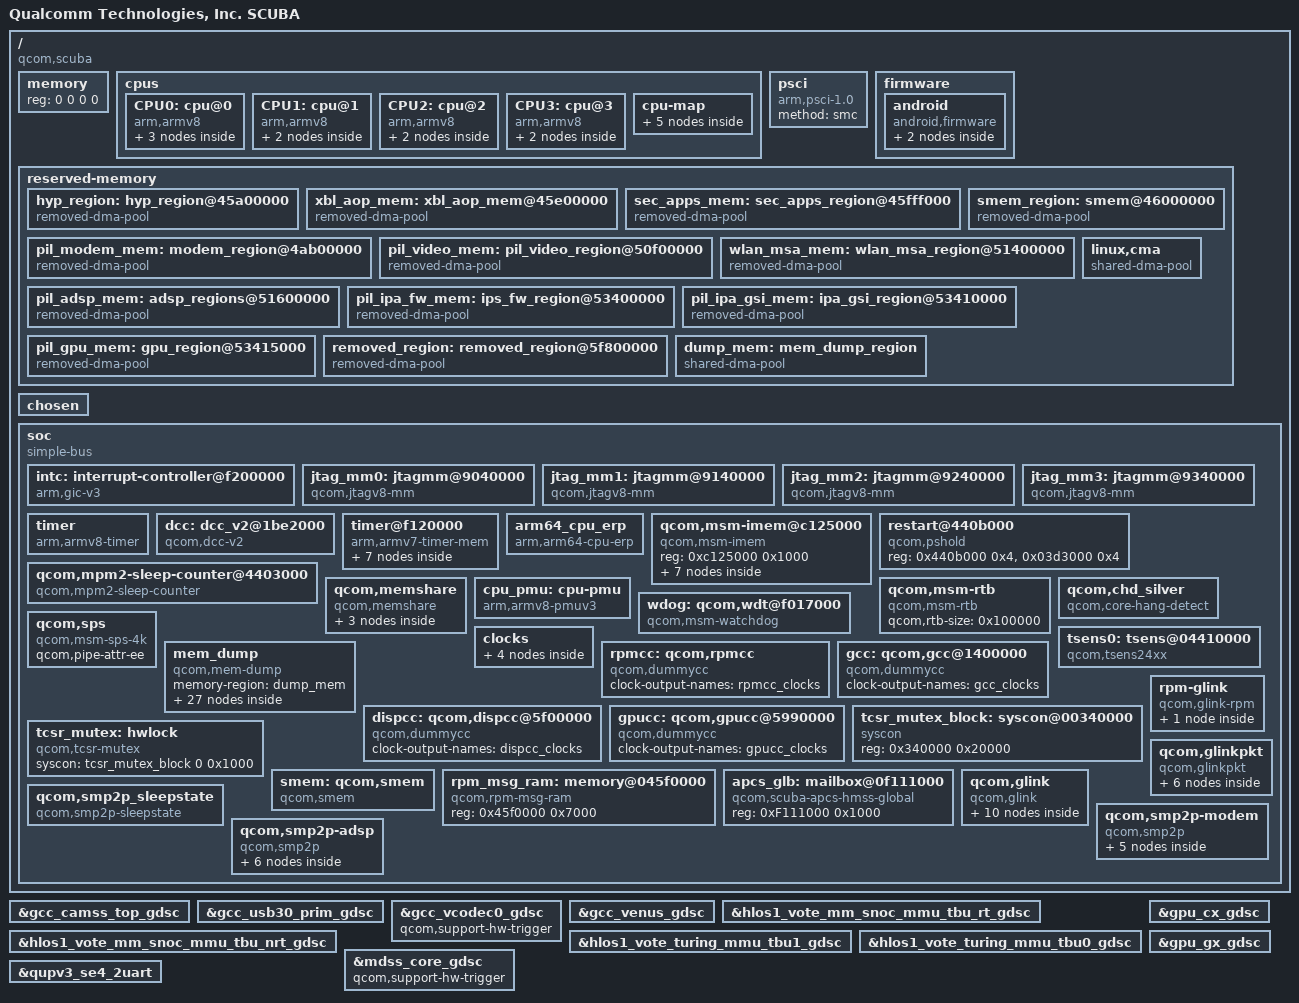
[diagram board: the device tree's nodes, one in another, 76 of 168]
#include <dt-bindings/interrupt-controller/arm-gic.h>
#include <dt-bindings/clock/qcom,dispcc-scuba.h>
#include <dt-bindings/clock/qcom,gcc-scuba.h>
#include <dt-bindings/clock/qcom,gpucc-scuba.h>
#include <dt-bindings/clock/qcom,rpmcc.h>

/ {
	model = "Qualcomm Technologies, Inc. SCUBA";
	compatible = "qcom,scuba";
	qcom,msm-id = <441 0x10000>;
	interrupt-parent = <&intc>;

	#address-cells = <2>;
	#size-cells = <2>;
	memory { device_type = "memory"; reg = <0 0 0 0>; };

	cpus {
		#address-cells = <2>;
		#size-cells = <0>;

		CPU0: cpu@0 {
			device_type = "cpu";
			compatible = "arm,armv8";
			reg = <0x0 0x0>;
			enable-method = "psci";
			capacity-dmips-mhz = <1024>;
			dynamic-power-coefficient = <100>;
			d-cache-size = <0x8000>;
			i-cache-size = <0x8000>;
			next-level-cache = <&L2_0>;
			L2_0: l2-cache {
				compatible = "arm,arch-cache";
				cache-level = <2>;
			};

			L1_I_0: l1-icache {
				compatible = "arm,arch-cache";
			};

			L1_D_0: l1-dcache {
				compatible = "arm,arch-cache";
			};
		};

		CPU1: cpu@1 {
			device_type = "cpu";
			compatible = "arm,armv8";
			reg = <0x0 0x1>;
			enable-method = "psci";
			capacity-dmips-mhz = <1024>;
			dynamic-power-coefficient = <100>;
			d-cache-size = <0x8000>;
			i-cache-size = <0x8000>;
			next-level-cache = <&L2_0>;

			L1_I_1: l1-icache {
				compatible = "arm,arch-cache";
			};

			L1_D_1: l1-dcache {
				compatible = "arm,arch-cache";
			};
		};

		CPU2: cpu@2 {
			device_type = "cpu";
			compatible = "arm,armv8";
			reg = <0x0 0x2>;
			enable-method = "psci";
			capacity-dmips-mhz = <1024>;
			dynamic-power-coefficient = <100>;
			d-cache-size = <0x8000>;
			i-cache-size = <0x8000>;
			next-level-cache = <&L2_0>;

			L1_I_2: l1-icache {
				compatible = "arm,arch-cache";
			};

			L1_D_2: l1-dcache {
				compatible = "arm,arch-cache";
			};
		};

		CPU3: cpu@3 {
			device_type = "cpu";
			compatible = "arm,armv8";
			reg = <0x0 0x3>;
			enable-method = "psci";
			capacity-dmips-mhz = <1024>;
			dynamic-power-coefficient = <100>;
			d-cache-size = <0x8000>;
			i-cache-size = <0x8000>;
			next-level-cache = <&L2_0>;

			L1_I_3: l1-icache {
				compatible = "arm,arch-cache";
			};

			L1_D_3: l1-dcache {
				compatible = "arm,arch-cache";
			};
		};

		cpu-map {
			cluster0 {
				core0 {
					cpu = <&CPU0>;
				};

				core1 {
					cpu = <&CPU1>;
				};

				core2 {
					cpu = <&CPU2>;
				};

				core3 {
					cpu = <&CPU3>;
				};
			};
		};
	};

	psci {
		compatible = "arm,psci-1.0";
		method = "smc";
	};

	firmware: firmware {
		android {
			compatible = "android,firmware";
			fstab {
				compatible = "android,fstab";
				vendor {
					compatible = "android,vendor";
					dev = "/dev/block/platform/soc/4744000.sdhci/by-name/vendor";
					type = "ext4";
					mnt_flags = "ro,barrier=1,discard";
					fsmgr_flags = "wait,slotselect";
					status = "ok";
				};
			};
		};
	};

	reserved-memory {
		#address-cells = <2>;
		#size-cells = <2>;
		ranges;

		hyp_region: hyp_region@45a00000 {
			compatible = "removed-dma-pool";
			no-map;
			reg = <0x0 0x45a00000 0x0 0x300000>;
		};

		xbl_aop_mem: xbl_aop_mem@45e00000 {
			compatible = "removed-dma-pool";
			no-map;
			reg = <0x0 0x45e00000 0x0 0x100000>;
		};

		sec_apps_mem: sec_apps_region@45fff000 {
			compatible = "removed-dma-pool";
			no-map;
			reg = <0x0 0x45fff000 0x0 0x1000>;
		};

		smem_region: smem@46000000 {
			compatible = "removed-dma-pool";
			no-map;
			reg = <0x0 0x46000000 0x0 0x200000>;
		};

		pil_modem_mem: modem_region@4ab00000 {
			compatible = "removed-dma-pool";
			no-map;
			reg = <0x0 0x4ab00000 0x0 0x6400000>;
		};

		pil_video_mem: pil_video_region@50f00000 {
			compatible = "removed-dma-pool";
			no-map;
			reg = <0x0 0x50f00000 0x0 0x500000>;
		};

		wlan_msa_mem: wlan_msa_region@51400000 {
			compatible = "removed-dma-pool";
			no-map;
			reg = <0x0 0x51400000 0x0 0x200000>;
		};

		pil_adsp_mem: adsp_regions@51600000 {
			compatible = "removed-dma-pool";
			no-map;
			reg = <0x0 0x51600000 0x0 0x1e00000>;
		};

		pil_ipa_fw_mem: ips_fw_region@53400000 {
			compatible = "removed-dma-pool";
			no-map;
			reg = <0x0 0x53400000 0x0 0x10000>;
		};

		pil_ipa_gsi_mem: ipa_gsi_region@53410000 {
			compatible = "removed-dma-pool";
			no-map;
			reg = <0x0 0x53410000 0x0 0x5000>;
		};

		pil_gpu_mem: gpu_region@53415000 {
			compatible = "removed-dma-pool";
			no-map;
			reg = <0x0 0x53415000 0x0 0x2000>;
		};

		removed_region: removed_region@5f800000 {
			compatible = "removed-dma-pool";
			no-map;
			reg = <0x0 0x5f800000 0x0 0x4100000>;
		};

		dump_mem: mem_dump_region {
			compatible = "shared-dma-pool";
			reusable;
			size = <0 0x800000>;
		};

		/* global autoconfigured region for contiguous allocations */
		linux,cma {
			compatible = "shared-dma-pool";
			alloc-ranges = <0x0 0x00000000 0x0 0xffffffff>;
			reusable;
			alignment = <0x0 0x400000>;
			size = <0x0 0x2000000>;
			linux,cma-default;
		};
	};

	chosen {
		bootargs = "rcupdate.rcu_expedited=1 rcu_nocbs=0-7";
	};

	soc: soc { };
};

&soc {
	#address-cells = <1>;
	#size-cells = <1>;
	ranges = <0 0 0 0xffffffff>;
	compatible = "simple-bus";

	intc: interrupt-controller@f200000 {
		compatible = "arm,gic-v3";
		#interrupt-cells = <3>;
		interrupt-controller;
		#redistributor-regions = <1>;
		redistributor-stride = <0x0 0x20000>;
		reg = <0xf200000 0x10000>,     /* GICD */
		      <0xf300000 0x100000>;    /* GICR * 8 */
		interrupts = <1 9 4>;
	};

	jtag_mm0: jtagmm@9040000 {
		compatible = "qcom,jtagv8-mm";
		reg = <0x9040000 0x1000>;
		reg-names = "etm-base";

		clocks = <&rpmcc RPM_SMD_QDSS_CLK>;
		clock-names = "core_clk";

		qcom,coresight-jtagmm-cpu = <&CPU0>;
	};

	jtag_mm1: jtagmm@9140000 {
		compatible = "qcom,jtagv8-mm";
		reg = <0x9140000 0x1000>;
		reg-names = "etm-base";

		clocks = <&rpmcc RPM_SMD_QDSS_CLK>;
		clock-names = "core_clk";

		qcom,coresight-jtagmm-cpu = <&CPU1>;
	};

	jtag_mm2: jtagmm@9240000 {
		compatible = "qcom,jtagv8-mm";
		reg = <0x9240000 0x1000>;
		reg-names = "etm-base";

		clocks = <&rpmcc RPM_SMD_QDSS_CLK>;
		clock-names = "core_clk";

		qcom,coresight-jtagmm-cpu = <&CPU2>;
	};

	jtag_mm3: jtagmm@9340000 {
		compatible = "qcom,jtagv8-mm";
		reg = <0x9340000 0x1000>;
		reg-names = "etm-base";

		clocks = <&rpmcc RPM_SMD_QDSS_CLK>;
		clock-names = "core_clk";

		qcom,coresight-jtagmm-cpu = <&CPU3>;
	};

	timer {
		compatible = "arm,armv8-timer";
		interrupts = <1 1 0xf08>,
			     <1 2 0xf08>,
			     <1 3 0xf08>,
			     <1 0 0xf08>;
		clock-frequency = <19200000>;
	};

	dcc: dcc_v2@1be2000 {
		compatible = "qcom,dcc-v2";
		reg = <0x1be2000 0x1000>,
			<0x1bee000 0x2000>;
		reg-names = "dcc-base", "dcc-ram-base";
		dcc-ram-offset = <0x2000>;
	};

	timer@f120000 {
		#address-cells = <1>;
		#size-cells = <1>;
		ranges;
		compatible = "arm,armv7-timer-mem";
		reg = <0xf120000 0x1000>;
		clock-frequency = <19200000>;

		frame@f121000 {
			frame-number = <0>;
			interrupts = <0 8 0x4>,
				     <0 7 0x4>;
			reg = <0xf121000 0x1000>,
			      <0xf122000 0x1000>;
		};

		frame@f123000 {
			frame-number = <1>;
			interrupts = <0 9 0x4>;
			reg = <0xf123000 0x1000>;
			status = "disabled";
		};

		frame@f124000 {
			frame-number = <2>;
			interrupts = <0 10 0x4>;
			reg = <0xf124000 0x1000>;
			status = "disabled";
		};

		frame@f125000 {
			frame-number = <3>;
			interrupts = <0 11 0x4>;
			reg = <0xf125000 0x1000>;
			status = "disabled";
		};

		frame@f126000 {
			frame-number = <4>;
			interrupts = <0 12 0x4>;
			reg = <0xf126000 0x1000>;
			status = "disabled";
		};

		frame@f127000 {
			frame-number = <5>;
			interrupts = <0 13 0x4>;
			reg = <0xf127000 0x1000>;
			status = "disabled";
		};

		frame@f128000 {
			frame-number = <6>;
			interrupts = <0 14 0x4>;
			reg = <0xf128000 0x1000>;
			status = "disabled";
		};
	};

	arm64_cpu_erp {
		compatible = "arm,arm64-cpu-erp";
		interrupt-names = "pri-dbe-irq",
				  "pri-ext-irq";
		interrupts = <0 43 4>,
			     <0 41 4>;
		poll-delay-ms = <5000>;
	};

	qcom,msm-imem@c125000 {
		compatible = "qcom,msm-imem";
		reg = <0xc125000 0x1000>;
		ranges = <0x0 0xc125000 0x1000>;
		#address-cells = <1>;
		#size-cells = <1>;

		mem_dump_table@10 {
			compatible = "qcom,msm-imem-mem_dump_table";
			reg = <0x10 0x8>;
		};

		restart_reason@65c {
			compatible = "qcom,msm-imem-restart_reason";
			reg = <0x65c 0x4>;
		};

		dload_type@1c {
			compatible = "qcom,msm-imem-dload-type";
			reg = <0x1c 0x4>;
		};

		boot_stats@6b0 {
			compatible = "qcom,msm-imem-boot_stats";
			reg = <0x6b0 0x20>;
		};

		kaslr_offset@6d0 {
			compatible = "qcom,msm-imem-kaslr_offset";
			reg = <0x6d0 0xc>;
		};

		pil@94c {
			compatible = "qcom,msm-imem-pil";
			reg = <0x94c 0xc8>;
		};

		diag_dload@c8 {
			compatible = "qcom,msm-imem-diag-dload";
			reg = <0xc8 0xc8>;
		};
	};

	restart@440b000 {
		compatible = "qcom,pshold";
		reg = <0x440b000 0x4>,
		      <0x03d3000 0x4>;
		reg-names = "pshold-base", "tcsr-boot-misc-detect";
	};

	qcom,mpm2-sleep-counter@4403000 {
		compatible = "qcom,mpm2-sleep-counter";
		reg = <0x4403000 0x1000>;
		clock-frequency = <32768>;
	};

	qcom,memshare {
		compatible = "qcom,memshare";

		qcom,client_1 {
			compatible = "qcom,memshare-peripheral";
			qcom,peripheral-size = <0x0>;
			qcom,client-id = <0>;
			qcom,allocate-boot-time;
			label = "modem";
		};

		qcom,client_2 {
			compatible = "qcom,memshare-peripheral";
			qcom,peripheral-size = <0x0>;
			qcom,client-id = <2>;
			label = "modem";
		};

		mem_client_3_size: qcom,client_3 {
			compatible = "qcom,memshare-peripheral";
			qcom,peripheral-size = <0x500000>;
			qcom,client-id = <1>;
			qcom,allocate-on-request;
			label = "modem";
		};
	};

	qcom,msm-rtb {
		compatible = "qcom,msm-rtb";
		qcom,rtb-size = <0x100000>;
	};

	cpu_pmu: cpu-pmu {
		compatible = "arm,armv8-pmuv3";
		qcom,irq-is-percpu;
		interrupts = <1 6 4>;
	};

	qcom,chd_silver {
		compatible = "qcom,core-hang-detect";
		label = "silver";
		qcom,threshold-arr = <0x0f1880b0 0x0f1980b0
				      0x0f1a80b0 0x0f1b80b0>;
		qcom,config-arr = <0x0f1880b8 0x0f1980b8
				   0x0f1a80b8 0x0f1b80b8>;
	};

	wdog: qcom,wdt@f017000 {
		compatible = "qcom,msm-watchdog";
		reg = <0xf017000 0x1000>;
		reg-names = "wdt-base";
		interrupts = <0 3 0>, <0 4 0>;
		qcom,bark-time = <11000>;
		qcom,pet-time = <9360>;
		qcom,ipi-ping;
		qcom,wakeup-enable;
	};

	qcom,sps {
		compatible = "qcom,msm-sps-4k";
		qcom,pipe-attr-ee;
	};

	tsens0:tsens@04410000 {
		compatible = "qcom,tsens24xx";
		reg = <0x04410000 0x8>,
			<0x04411000 0x1ff>;
		reg-names = "tsens_srot_physical",
				"tsens_tm_physical";
		interrupts = <0 275 0>, <0 190 0>;
		interrupt-names = "tsens-upper-lower", "tsens-critical";
		#thermal-sensor-cells = <1>;
	};

	mem_dump {
		compatible = "qcom,mem-dump";
		memory-region = <&dump_mem>;

		c0_context {
			qcom,dump-size = <0x800>;
			qcom,dump-id = <0x0>;
		};

		c1_context {
			qcom,dump-size = <0x800>;
			qcom,dump-id = <0x1>;
		};

		c2_context {
			qcom,dump-size = <0x800>;
			qcom,dump-id = <0x2>;
		};

		c3_context {
			qcom,dump-size = <0x800>;
			qcom,dump-id = <0x3>;
		};

		c0_scandump {
			qcom,dump-size = <0x40000>;
			qcom,dump-id = <0x130>;
		};

		c1_scandump {
			qcom,dump-size = <0x40000>;
			qcom,dump-id = <0x131>;
		};

		c2_scandump {
			qcom,dump-size = <0x40000>;
			qcom,dump-id = <0x132>;
		};

		c3_scandump {
			qcom,dump-size = <0x40000>;
			qcom,dump-id = <0x133>;
		};

		l1_icache0 {
			qcom,dump-size = <0x9040>;
			qcom,dump-id = <0x60>;
		};

		l1_icache1 {
			qcom,dump-size = <0x9040>;
			qcom,dump-id = <0x61>;
		};

		l1_icache2 {
			qcom,dump-size = <0x9040>;
			qcom,dump-id = <0x62>;
		};

		l1_icache3 {
			qcom,dump-size = <0x9040>;
			qcom,dump-id = <0x63>;
		};

		l1_dcache0 {
			qcom,dump-size = <0x9040>;
			qcom,dump-id = <0x80>;
		};

		l1_dcache1 {
			qcom,dump-size = <0x9040>;
			qcom,dump-id = <0x81>;
		};

		l1_dcache2 {
			qcom,dump-size = <0x9040>;
			qcom,dump-id = <0x82>;
		};

		l1_dcache3 {
			qcom,dump-size = <0x9040>;
			qcom,dump-id = <0x83>;
		};

		l2_tlb0 {
			qcom,dump-size = <0x2000>;
			qcom,dump-id = <0x120>;
		};

		l2_tlb1 {
			qcom,dump-size = <0x2000>;
			qcom,dump-id = <0x121>;
		};

		l2_tlb2 {
			qcom,dump-size = <0x2000>;
			qcom,dump-id = <0x122>;
		};

		l2_tlb3 {
			qcom,dump-size = <0x2000>;
			qcom,dump-id = <0x123>;
		};

		rpm_sw {
			qcom,dump-size = <0x28000>;
			qcom,dump-id = <0xea>;
		};

		pmic {
			qcom,dump-size = <0x10000>;
			qcom,dump-id = <0xe4>;
		};

		fcm {
			qcom,dump-size = <0x8400>;
			qcom,dump-id = <0xee>;
		};

		tmc_etf {
			qcom,dump-size = <0x8000>;
			qcom,dump-id = <0xf0>;
		};

		etr_reg {
			qcom,dump-size = <0x1000>;
			qcom,dump-id = <0x100>;
		};

		etf_reg {
			qcom,dump-size = <0x1000>;
			qcom,dump-id = <0x101>;
		};

		misc_data {
			qcom,dump-size = <0x1000>;
			qcom,dump-id = <0xe8>;
		};
	};
	clocks {
		xo_board: xo-board {
			compatible = "fixed-clock";
			clock-frequency = <38400000>;
			clock-output-names = "xo_board";
			#clock-cells = <0>;
		};

		sleep_clk: sleep-clk {
			compatible = "fixed-clock";
			clock-frequency = <32764>;
			clock-output-names = "chip_sleep_clk";
			#clock-cells = <0>;
		};

		bi_tcxo: bi_tcxo {
			compatible = "fixed-factor-clock";
			clock-mult = <1>;
			clock-div = <2>;
			clocks = <&xo_board>;
			#clock-cells = <0>;
		};

		bi_tcxo_ao: bi_tcxo_ao {
			compatible = "fixed-factor-clock";
			clock-mult = <1>;
			clock-div = <2>;
			clocks = <&xo_board>;
			#clock-cells = <0>;
		};
	};

	rpmcc: qcom,rpmcc {
		compatible = "qcom,dummycc";
		clock-output-names = "rpmcc_clocks";
		#clock-cells = <1>;
		#reset-cells = <1>;
	};

	gcc: qcom,gcc@1400000 {
		compatible = "qcom,dummycc";
		clock-output-names = "gcc_clocks";
		#clock-cells = <1>;
		#reset-cells = <1>;
	};

	dispcc: qcom,dispcc@5f00000 {
		compatible = "qcom,dummycc";
		clock-output-names = "dispcc_clocks";
		#clock-cells = <1>;
		#reset-cells = <1>;
	};

	gpucc: qcom,gpucc@5990000 {
		compatible = "qcom,dummycc";
		clock-output-names = "gpucc_clocks";
		#clock-cells = <1>;
		#reset-cells = <1>;
	};

	tcsr_mutex_block: syscon@00340000 {
		compatible = "syscon";
		reg = <0x340000 0x20000>;
	};

	tcsr_mutex: hwlock {
		compatible = "qcom,tcsr-mutex";
		syscon = <&tcsr_mutex_block 0 0x1000>;
		#hwlock-cells = <1>;
	};

	smem: qcom,smem {
		compatible = "qcom,smem";
		memory-region = <&smem_region>;
		hwlocks = <&tcsr_mutex 3>;
	};

	rpm_msg_ram: memory@045f0000 {
			compatible = "qcom,rpm-msg-ram";
			reg = <0x45f0000 0x7000>;
	};

	apcs_glb: mailbox@0f111000 {
		compatible = "qcom,scuba-apcs-hmss-global";
		reg = <0xF111000 0x1000>;

		#mbox-cells = <1>;
	};

	rpm-glink {
		compatible = "qcom,glink-rpm";
		interrupts = <GIC_SPI 194 IRQ_TYPE_EDGE_RISING>;
		qcom,rpm-msg-ram = <&rpm_msg_ram>;
		mboxes = <&apcs_glb 0>;

		qcom,rpm_glink_ssr {
			qcom,glink-channels = "glink_ssr";
			qcom,notify-edges = <&glink_modem>,
					    <&glink_adsp>;
		};

	};

	qcom,glink {
		compatible = "qcom,glink";
		#address-cells = <1>;
		#size-cells = <1>;
		ranges;

		glink_modem: modem {
			qcom,remote-pid = <1>;
			transport = "smem";
			mboxes = <&apcs_glb 12>;
			mbox-names = "mpss_smem";
			interrupts = <GIC_SPI 68 IRQ_TYPE_EDGE_RISING>;

			label = "modem";
			qcom,glink-label = "mpss";

			qcom,modem_qrtr {
				qcom,glink-channels = "IPCRTR";
				qcom,low-latency;
				qcom,intents = <0x800  5
						0x2000 3
						0x4400 2>;
			};

			qcom,msm_fastrpc_rpmsg {
				compatible = "qcom,msm-fastrpc-rpmsg";
				qcom,glink-channels = "fastrpcglink-apps-dsp";
				qcom,intents = <0x64 64>;
			};

			qcom,modem_ds {
				qcom,glink-channels = "DS";
				qcom,intents = <0x4000 2>;
			};

			qcom,modem_glink_ssr {
				qcom,glink-channels = "glink_ssr";
				qcom,notify-edges = <&glink_adsp>;
			};
		};

		glink_adsp: adsp {
			qcom,remote-pid = <2>;
			transport = "smem";
			mboxes = <&apcs_glb 8>;
			mbox-names = "adsp_smem";
			interrupts = <GIC_SPI 277 IRQ_TYPE_EDGE_RISING>;

			label = "adsp";
			qcom,glink-label = "lpass";

			qcom,adsp_qrtr {
				qcom,glink-channels = "IPCRTR";
				qcom,low-latency;
				qcom,intents = <0x800  5
						0x2000 3
						0x4400 2>;
			};

			qcom,apr_tal_rpmsg {
				qcom,glink-channels = "apr_audio_svc";
				qcom,intents = <0x200 20>;
			};

			qcom,msm_fastrpc_rpmsg {
				compatible = "qcom,msm-fastrpc-rpmsg";
				qcom,glink-channels = "fastrpcglink-apps-dsp";
				qcom,intents = <0x64 64>;
			};

			qcom,adsp_glink_ssr {
				qcom,glink-channels = "glink_ssr";
				qcom,notify-edges = <&glink_modem>;
			};
		};
	};

	qcom,glinkpkt {
		compatible = "qcom,glinkpkt";

		qcom,glinkpkt-at-mdm0 {
			qcom,glinkpkt-edge = "mpss";
			qcom,glinkpkt-ch-name = "DS";
			qcom,glinkpkt-dev-name = "at_mdm0";
		};

		qcom,glinkpkt-apr-apps2 {
			qcom,glinkpkt-edge = "adsp";
			qcom,glinkpkt-ch-name = "apr_apps2";
			qcom,glinkpkt-dev-name = "apr_apps2";
		};

		qcom,glinkpkt-data40-cntl {
			qcom,glinkpkt-edge = "mpss";
			qcom,glinkpkt-ch-name = "DATA40_CNTL";
			qcom,glinkpkt-dev-name = "smdcntl8";
		};

		qcom,glinkpkt-data1 {
			qcom,glinkpkt-edge = "mpss";
			qcom,glinkpkt-ch-name = "DATA1";
			qcom,glinkpkt-dev-name = "smd7";
		};

		qcom,glinkpkt-data4 {
			qcom,glinkpkt-edge = "mpss";
			qcom,glinkpkt-ch-name = "DATA4";
			qcom,glinkpkt-dev-name = "smd8";
		};

		qcom,glinkpkt-data11 {
			qcom,glinkpkt-edge = "mpss";
			qcom,glinkpkt-ch-name = "DATA11";
			qcom,glinkpkt-dev-name = "smd11";
		};
	};

	qcom,smp2p_sleepstate {
		compatible = "qcom,smp2p-sleepstate";
		qcom,smem-states = <&sleepstate_smp2p_out 0>;
		interrupt-parent = <&sleepstate_smp2p_in>;
		interrupts = <0 0>;
		interrupt-names = "smp2p-sleepstate-in";
	};

	qcom,smp2p-modem {
		compatible = "qcom,smp2p";
		qcom,smem = <435>, <428>;
		interrupts = <GIC_SPI 70 IRQ_TYPE_EDGE_RISING>;
		mboxes = <&apcs_glb 14>;
		qcom,local-pid = <0>;
		qcom,remote-pid = <1>;

		modem_smp2p_out: master-kernel {
			qcom,entry-name = "master-kernel";
			#qcom,smem-state-cells = <1>;
		};

		modem_smp2p_in: slave-kernel {
			qcom,entry-name = "slave-kernel";
			interrupt-controller;
			#interrupt-cells = <2>;
		};

		smp2p_ipa_1_out: qcom,smp2p-ipa-1-out {
			qcom,entry-name = "ipa";
			#qcom,smem-state-cells = <1>;
		};

		/* ipa - inbound entry from mss */
		smp2p_ipa_1_in: qcom,smp2p-ipa-1-in {
			qcom,entry-name = "ipa";
			interrupt-controller;
			#interrupt-cells = <2>;
		};

		smp2p_wlan_1_in: qcom,smp2p-wlan-1-in {
			qcom,entry-name = "wlan";
			interrupt-controller;
			#interrupt-cells = <2>;
		};

	};

	qcom,smp2p-adsp {
		compatible = "qcom,smp2p";
		qcom,smem = <443>, <429>;
		interrupts = <GIC_SPI 279 IRQ_TYPE_EDGE_RISING>;
		mboxes = <&apcs_glb 10>;
		qcom,local-pid = <0>;
		qcom,remote-pid = <2>;

		adsp_smp2p_out: master-kernel {
			qcom,entry-name = "master-kernel";
			#qcom,smem-state-cells = <1>;
		};

		adsp_smp2p_in: slave-kernel {
			qcom,entry-name = "slave-kernel";
			interrupt-controller;
			#interrupt-cells = <2>;
		};

		smp2p_rdbg2_out: qcom,smp2p-rdbg2-out {
			qcom,entry-name = "rdbg";
			#qcom,smem-state-cells = <1>;
		};

		smp2p_rdbg2_in: qcom,smp2p-rdbg2-in {
			qcom,entry-name = "rdbg";
			interrupt-controller;
			#interrupt-cells = <2>;
		};

		sleepstate_smp2p_out: sleepstate-out {
			qcom,entry-name = "sleepstate";
			#qcom,smem-state-cells = <1>;
		};

		sleepstate_smp2p_in: qcom,sleepstate-in {
			qcom,entry-name = "sleepstate_see";
			interrupt-controller;
			#interrupt-cells = <2>;
		};
	};
};

#include "scuba-pinctrl.dtsi"
#include "scuba-ion.dtsi"
#include "scuba-stub-regulator.dtsi"
#include "scuba-gdsc.dtsi"
#include "scuba-qupv3.dtsi"
#include "scuba-usb.dtsi"

&gcc_camss_top_gdsc {
	status = "ok";
};

&gcc_usb30_prim_gdsc {
	status = "ok";
};

&gcc_vcodec0_gdsc {
	qcom,support-hw-trigger;
	status = "ok";
};

&gcc_venus_gdsc {
	status = "ok";
};

&hlos1_vote_mm_snoc_mmu_tbu_rt_gdsc {
	status = "ok";
};

&hlos1_vote_mm_snoc_mmu_tbu_nrt_gdsc {
	status = "ok";
};

&hlos1_vote_turing_mmu_tbu1_gdsc {
	status = "ok";
};

&hlos1_vote_turing_mmu_tbu0_gdsc {
	status = "ok";
};

&mdss_core_gdsc {
	qcom,support-hw-trigger;
	status = "ok";
};

&gpu_cx_gdsc {
	status = "ok";
};

&gpu_gx_gdsc {
	status = "ok";
};

&qupv3_se4_2uart {
	status = "ok";
};
